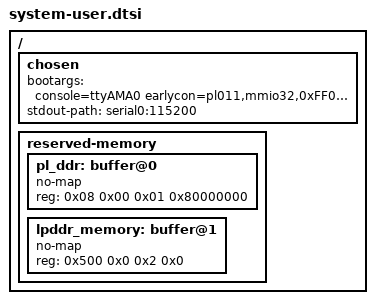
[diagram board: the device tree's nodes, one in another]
/******************************************************************************
* Copyright (C) 2020-2022 Xilinx, Inc. All rights reserved.
* Copyright (C) 2022-2023 Advanced Micro Devices, Inc. All rights reserved.
* SPDX-License-Identifier: MIT
******************************************************************************/
/*
 * /include/ "system-conf.dtsi"
 * Adding directly contents of system-conf file until CR-1139794 is fixed
 */
/ {
        chosen {
                bootargs = "console=ttyAMA0  earlycon=pl011,mmio32,0xFF000000,115200n8 clk_ignore_unused root=/dev/mmcblk0p2 rw rootwait cma=512M";
                stdout-path = "serial0:115200n8";
        };
};

/ {
	chosen {
		stdout-path = "serial0:115200";
	};

	reserved-memory {
                #address-cells = <2>;
                #size-cells = <2>;
                ranges;
                pl_ddr: buffer@0 {
                        no-map;
                        reg = <0x08 0x00 0x01 0x80000000>;
                };
                lpddr_memory: buffer@1 {
                        no-map;
                        reg = <0x500 0x0 0x2 0x0>;
                };
        }; 
};

